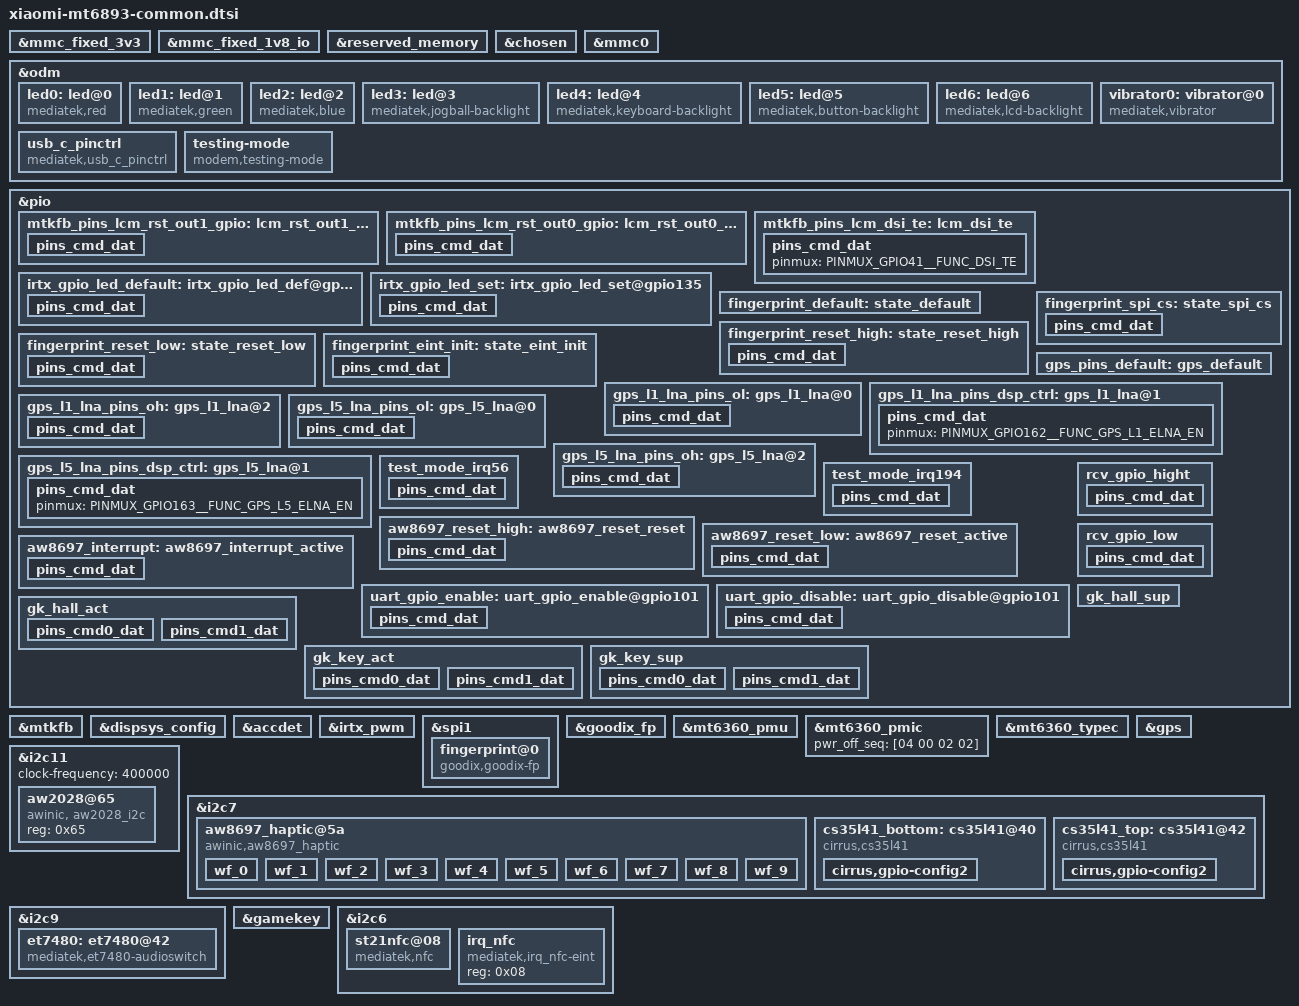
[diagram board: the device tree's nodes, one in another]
/*
 * Mediatek's mt6893 SoC device tree source
 *
 * Copyright (C) 2016 MediaTek Inc.
 * Copyright (C) 2021 XiaoMi, Inc.
 *
 * This program is free software; you can redistribute it and/or modify
 * it under the terms of the GNU General Public License version 2 as
 * published by the Free Software Foundation.
 *
 * This program is distributed in the hope that it will be useful,
 * but WITHOUT ANY WARRANTY; without even the implied warranty of
 * MERCHANTABILITY or FITNESS FOR A PARTICULAR PURPOSE.
 * See http://www.gnu.org/licenses/gpl-2.0.html for more details.
 */
/dts-v1/;
/plugin/;
#include <dt-bindings/interrupt-controller/irq.h>
#include <dt-bindings/interrupt-controller/arm-gic.h>
#include <dt-bindings/spmi/spmi.h>
#include <dt-bindings/pinctrl/mt6885-pinfunc.h>

&mmc_fixed_3v3 {
	status = "okay";
	regulator-name = "mmc_power";
	regulator-min-microvolt = <3300000>;
	regulator-max-microvolt = <3300000>;
	enable-active-high;
	regulator-always-on;
};

&mmc_fixed_1v8_io {
	status = "okay";
	regulator-name = "mmc_io";
	regulator-min-microvolt = <1800000>;
	regulator-max-microvolt = <1800000>;
	enable-active-high;
	regulator-always-on;
};

&reserved_memory {
};

/* chosen */
&chosen {

	atag,videolfb-fb_base_l = <0x7e020000>;
	atag,videolfb-fb_base_h = <0x0>;
	atag,videolfb-islcmfound = <1>;
	atag,videolfb-islcm_inited = <0>;
	atag,videolfb-fps= <6000>;
	atag,videolfb-vramSize= <0x1be0000>;
	atag,videolfb-lcmname=
		"nt35595_fhd_dsi_cmd_truly_nt50358_drv";
};

&mmc0 {
	status = "okay";
	/* pinctrl-names = "default", "state_uhs"; */
	/* pinctrl-0 = <&mmc0_pins_default>; */
	/* pinctrl-1 = <&mmc0_pins_uhs>; */
	bus-width = <8>;
	max-frequency = <5000000>;
	cap-mmc-highspeed;
	no-sdio;
	no-sd;
	vmmc-supply = <&mmc_fixed_3v3>;
	vqmmc-supply = <&mmc_fixed_1v8_io>;
	non-removable;
};

&odm {
	led0:led@0 {
		compatible = "mediatek,red";
		led_mode = <0>;
		data = <1>;
		pwm_config = <0 0 0 0 0>;
	};
	led1:led@1 {
		compatible = "mediatek,green";
		led_mode = <0>;
		data = <1>;
		pwm_config = <0 0 0 0 0>;
	};
	led2:led@2 {
		compatible = "mediatek,blue";
		led_mode = <0>;
		data = <1>;
		pwm_config = <0 0 0 0 0>;
	};
	led3:led@3 {
		compatible = "mediatek,jogball-backlight";
		led_mode = <0>;
		data = <1>;
		pwm_config = <0 0 0 0 0>;
	};
	led4:led@4 {
		compatible = "mediatek,keyboard-backlight";
		led_mode = <0>;
		data = <1>;
		pwm_config = <0 0 0 0 0>;
	};
	led5:led@5 {
		compatible = "mediatek,button-backlight";
		led_mode = <0>;
		data = <1>;
		pwm_config = <0 0 0 0 0>;
	};
	led6:led@6 {
		compatible = "mediatek,lcd-backlight";
		led_mode = <4>;
		data = <1>;
		pwm_config = <0 1 0 0 0>;
	};
	vibrator0:vibrator@0 {
		compatible = "mediatek,vibrator";
		vib_timer = <25>;
		vib_limit = <9>;
		vib_vol= <11>;
	};
	usb_c_pinctrl:usb_c_pinctrl {
		compatible = "mediatek,usb_c_pinctrl";
	};
};

/* DISPSYS GPIO standardization */
&pio {
	mtkfb_pins_lcm_rst_out1_gpio: lcm_rst_out1_gpio {
		pins_cmd_dat {
			pinmux = <PINMUX_GPIO42__FUNC_GPIO42>;
			slew-rate = <1>;
			output-high;
		};
	};

	mtkfb_pins_lcm_rst_out0_gpio: lcm_rst_out0_gpio {
		pins_cmd_dat {
			pinmux = <PINMUX_GPIO42__FUNC_GPIO42>;
			slew-rate = <1>;
			output-low;
		};
	};

	mtkfb_pins_lcm_dsi_te: lcm_dsi_te {
		pins_cmd_dat {
			pinmux = <PINMUX_GPIO41__FUNC_DSI_TE>;
		};
	};
};

&mtkfb {
	pinctrl-names = "lcm_rst_out1_gpio", "lcm_rst_out0_gpio",
		"mode_te_te";
	pinctrl-0 = <&mtkfb_pins_lcm_rst_out1_gpio>;
	pinctrl-1 = <&mtkfb_pins_lcm_rst_out0_gpio>;
	pinctrl-2 = <&mtkfb_pins_lcm_dsi_te>;
	status = "okay";
};

&dispsys_config {
	pinctrl-names =
		"lcm_rst_out1_gpio", "lcm_rst_out0_gpio",
		"mode_te_te";
	pinctrl-0 = <&mtkfb_pins_lcm_rst_out1_gpio>;
	pinctrl-1 = <&mtkfb_pins_lcm_rst_out0_gpio>;
	pinctrl-2 = <&mtkfb_pins_lcm_dsi_te>;
	status = "okay";
};
/* DISPSYS GPIO standardization end */

/* accdet start */
&accdet {
	/* accdet micbias voltage: 0x09:2.85v 0x08:2.8v 0x07,
	 * 2.7v;0x05,2.5v;0x02,1.9v
	 */
	accdet-mic-vol = <8>;
	/* accdet pwm_width, pwm_thresh, fall_delay, rise_delay
	 * debounce0, debounce1, debounce3, debounce4
	 * eint pwm_width, eint pwm_thresh
	 * eint deb(debounce0, debounce1, debounce2, debounce3), inv_debounce
	 */
	headset-mode-setting = <0x500 0x500 1 0x1f0
				0x800 0x800 0x20 0x44
				0x4 0x1
				0x5 0x3 0x3 0x5 0xe>;
	accdet-plugout-debounce = <1>;
	/*1:ACC mode, 2:low cost without in bias, 6:low cost with in bias*/
	accdet-mic-mode = <2>;
	/*0--MD_MAX--UP_MAX--DW_MAX*/
	headset-three-key-threshold = <0 80 220 400>;
	headset-three-key-threshold-CDD = <0 121 192 600>;
	/*0--MD_MAX--VOICE_MAX--UP_MAX--DW_MAX*/
	headset-four-key-threshold = <0 58 121 192 400>;

	/* select VTH to 2v and 500k, use internal resitance */
	eint_use_ext_res = <0>;
	status = "okay";
};
/* accdet end */

/* IRTX GPIO Start */
&irtx_pwm {
	pwm_ch = <0>;
	pinctrl-names = "irtx_gpio_led_default", "irtx_gpio_led_set";
	pinctrl-0 = <&irtx_gpio_led_default>;
	pinctrl-1 = <&irtx_gpio_led_set>;
	status = "okay";
};
&pio {
	/* IRTX GPIO Settings -Start */
	/* default: GPIO0, output, high */
	irtx_gpio_led_default:irtx_gpio_led_def@gpio135 {
		pins_cmd_dat {
			pinmux = <PINMUX_GPIO135__FUNC_GPIO135>;
			slew-rate = <1>;
			bias-disable;
			output-low;
			input-schmitt-enable = <0>;
		};
	};

	irtx_gpio_led_set:irtx_gpio_led_set@gpio135 {
		pins_cmd_dat {
			pinmux = <PINMUX_GPIO135__FUNC_PWM_0>;
			slew-rate = <1>;
			output-high;
		};
	};
}; /* IRTX GPIO Settings -End */

/* FINGERPRINT start */
&spi1 {
	#address-cells = <1>;
	#size-cells = <0>;
	fingerprint@0 {
		compatible = "goodix,goodix-fp";
		reg = <0>;
		spi-max-frequency = <8000000>;
		netlink-event = <30>;
		vfp-supply = <&mt_pmic_vfp_ldo_reg>;
		power-type = <1>;
		status = "okay";
	};
};

&goodix_fp {
	pinctrl-names = "default", "reset_high", "reset_low", "eint_init", "spi_cs";
	pinctrl-0 = <&fingerprint_default>;
	pinctrl-1 = <&fingerprint_reset_high>;
	pinctrl-2 = <&fingerprint_reset_low>;
	pinctrl-3 = <&fingerprint_eint_init>;
	pinctrl-4 = <&fingerprint_spi_cs>;
	fpc,gpio_irq = <&pio 15 0>;
	interrupt-parent = <&pio>;
	interrupts = <15 IRQ_TYPE_EDGE_RISING 15 0>;
	status = "okay";
};

&pio {
	fingerprint_default: state_default {
	};
	fingerprint_reset_high: state_reset_high {
		pins_cmd_dat {
			pinmux = <PINMUX_GPIO14__FUNC_GPIO14>;
			slew-rate = <1>;
			output-high;
		};
	};
	fingerprint_reset_low: state_reset_low {
		pins_cmd_dat {
			pinmux = <PINMUX_GPIO14__FUNC_GPIO14>;
			slew-rate = <1>;
			output-low;
		};
	};
	fingerprint_eint_init: state_eint_init {
		pins_cmd_dat {
			pinmux = <PINMUX_GPIO15__FUNC_GPIO15>;
			slew-rate = <0>;
			bias-pull-up = <MTK_PUPD_SET_R1R0_10>;
			input-schmitt-enable;
		};
	};
	fingerprint_spi_cs: state_spi_cs {
		pins_cmd_dat {
			pinmux = <PINMUX_GPIO157__FUNC_SPI1_A_CSB>;
			slew-rate = <0>;
			bias-disable;
		};
	};
};
/* FINGERPRINT end */

&mt6360_pmu {
	mt6360,intr_gpio_num = <24>; /* direct defined GPIO num */
	mt6360,intr_gpio = <&pio 24 0x0>;
};

&mt6360_pmic {
	pwr_off_seq = [04 00 02 02];
};

&mt6360_typec {
	mt6360pd,intr_gpio_num = <25>; /* direct defined GPIO num */
	mt6360pd,intr_gpio = <&pio 25 0x0>;
};

/* USB SWITCH GPIO start
&pio {
	usb_default: usb_default {
	};

	gpio_redriver_c1_init: c1_init {
		pins_cmd_dat {
			pinmux = <PINMUX_GPIO113__FUNC_GPIO113>;
			slew-rate = <1>;
			output-low;
		};
	};

	gpio_redriver_c1_low: c1_low {
		pins_cmd_dat {
			pinmux = <PINMUX_GPIO113__FUNC_GPIO113>;
			slew-rate = <1>;
			output-low;
		};
	};

	gpio_redriver_c1_hiz: c1_highz {
		pins_cmd_dat {
			pinmux = <PINMUX_GPIO113__FUNC_GPIO113>;
			slew-rate= <0>;
			bias-disable;
		};
	};

	gpio_redriver_c1_high: c1_high {
		pins_cmd_dat {
			pinmux = <PINMUX_GPIO113__FUNC_GPIO113>;
			slew-rate = <1>;
			output-high;
		};
	};

	gpio_redriver_c2_init: c2_init {
		pins_cmd_dat {
			pinmux = <PINMUX_GPIO112__FUNC_GPIO112>;
			slew-rate = <1>;
			output-low;
		};
	};

	gpio_redriver_c2_low: c2_low {
		pins_cmd_dat {
			pinmux = <PINMUX_GPIO112__FUNC_GPIO112>;
			slew-rate = <1>;
			output-low;
		};
	};

	gpio_redriver_c2_hiz: c2_highz {
		pins_cmd_dat {
			pinmux = <PINMUX_GPIO112__FUNC_GPIO112>;
			slew-rate= <0>;
			bias-disable;
		};
	};

	gpio_redriver_c2_high: c2_high {
		pins_cmd_dat {
			pinmux = <PINMUX_GPIO112__FUNC_GPIO112>;
			slew-rate = <1>;
			output-high;
		};
	};

	gpio_u3_switch_sel1: u3_sw_sel1 {
		pins_cmd_dat {
			pinmux = <PINMUX_GPIO111__FUNC_GPIO111>;
			slew-rate = <1>;
			output-low;
		};
	};

	gpio_u3_switch_sel2: u3_sw_sel2 {
		pins_cmd_dat {
			pinmux = <PINMUX_GPIO111__FUNC_GPIO111>;
			slew-rate = <1>;
			output-high;
		};
	};

	gpio_u3_switch_enable: u3_sw_en {
	};

	gpio_u3_switch_disable: u3_sw_dis {
	};
};

&usb_c_pinctrl {
	pinctrl-names = "usb_default",
		"redrv_c1_init",
		"redrv_c1_low",
		"redrv_c1_hiz",
		"redrv_c1_high",
		"redrv_c2_init",
		"redrv_c2_low",
		"redrv_c2_hiz",
		"redrv_c2_high",
		"switch_sel1",
		"switch_sel2",
		"switch_enable",
		"switch_disable";

	pinctrl-0 = <&usb_default>;
	pinctrl-1 = <&gpio_redriver_c1_init>;
	pinctrl-2 = <&gpio_redriver_c1_low>;
	pinctrl-3 = <&gpio_redriver_c1_hiz>;
	pinctrl-4 = <&gpio_redriver_c1_high>;
	pinctrl-5 = <&gpio_redriver_c2_init>;
	pinctrl-6 = <&gpio_redriver_c2_low>;
	pinctrl-7 = <&gpio_redriver_c2_hiz>;
	pinctrl-8 = <&gpio_redriver_c2_high>;
	pinctrl-9 = <&gpio_u3_switch_sel1>;
	pinctrl-10 = <&gpio_u3_switch_sel2>;
	pinctrl-11 = <&gpio_u3_switch_enable>;
	pinctrl-12 = <&gpio_u3_switch_disable>;
	status = "okay";

	usb_switch-data {
		en_pin_num = <0>;
		en_pin_val = <0>;
		sel_pin_num = <111>;
		sel_pin_val = <1>;
		c1_pin_num = <113>;
		c1_pin_val = <2>;
		c2_pin_num = <112>;
		c2_pin_val = <1>;
	};
};
USB SWITCH GPIO end */

/* GPS GPIO standardization start */
&pio {
	gps_pins_default: gps_default {
	};

	gps_l1_lna_pins_ol: gps_l1_lna@0 {
		pins_cmd_dat {
			pinmux = <PINMUX_GPIO162__FUNC_GPIO162>;
			output-low;
		};
	};
	gps_l1_lna_pins_dsp_ctrl: gps_l1_lna@1 {
		pins_cmd_dat {
			pinmux = <PINMUX_GPIO162__FUNC_GPS_L1_ELNA_EN>;
		};
	};
	gps_l1_lna_pins_oh: gps_l1_lna@2 {
		pins_cmd_dat {
			pinmux = <PINMUX_GPIO162__FUNC_GPIO162>;
			output-high;
		};
	};

	gps_l5_lna_pins_ol: gps_l5_lna@0 {
		pins_cmd_dat {
			pinmux = <PINMUX_GPIO163__FUNC_GPIO163>;
			output-low;
		};
	};
	gps_l5_lna_pins_dsp_ctrl: gps_l5_lna@1 {
		pins_cmd_dat {
			pinmux = <PINMUX_GPIO163__FUNC_GPS_L5_ELNA_EN>;
		};
	};
	gps_l5_lna_pins_oh: gps_l5_lna@2 {
		pins_cmd_dat {
			pinmux = <PINMUX_GPIO163__FUNC_GPIO163>;
			output-high;
		};
	};
};

&gps {
	pinctrl-names = "default",
		"gps_l1_lna_disable",
		"gps_l1_lna_dsp_ctrl",
		"gps_l1_lna_enable",
		"gps_l5_lna_disable",
		"gps_l5_lna_dsp_ctrl",
		"gps_l5_lna_enable";
	pinctrl-0 = <&gps_pins_default>;
	pinctrl-1 = <&gps_l1_lna_pins_ol>;
	pinctrl-2 = <&gps_l1_lna_pins_dsp_ctrl>;
	pinctrl-3 = <&gps_l1_lna_pins_oh>;
	pinctrl-4 = <&gps_l5_lna_pins_ol>;
	pinctrl-5 = <&gps_l5_lna_pins_dsp_ctrl>;
	pinctrl-6 = <&gps_l5_lna_pins_oh>;
	status = "okay";
};
/* GPS GPIO standardization end */

&i2c11 {
	clock-frequency = <400000>;
	aw2028@65 {
		compatible = "awinic, aw2028_i2c";
		reg = <0x65>;
		status = "okay";
	};
};

&odm {
	testing-mode {
		compatible = "modem,testing-mode";
		status-gpio = <&pio 56 0>, <&pio 194 0>;
		debounce-time = <30>;
		pinctrl-names = "default";
		pinctrl-0 = <&test_mode_irq56 &test_mode_irq194>;
	};
};

&pio {
	test_mode_irq56: test_mode_irq56 {
                pins_cmd_dat {
			pinmux = <PINMUX_GPIO56__FUNC_GPIO56>;
			drive-strength = <2>;
			bias-disable;
			input-enable;
		};
	};

    test_mode_irq194: test_mode_irq194 {
        	pins_cmd_dat {
			pinmux = <PINMUX_GPIO194__FUNC_GPIO194>;
			drive-strength = <2>;
			bias-disable;
			input-enable;
		};
    };
};

/* AW8697 Haptic start */
&pio {
	aw8697_reset_high: aw8697_reset_reset {
		pins_cmd_dat {
			pinmux = <PINMUX_GPIO129__FUNC_GPIO129>;
			drive-strength = <2>;
			bias-disable;
			output-high;
		};
	};
	aw8697_reset_low: aw8697_reset_active {
		pins_cmd_dat {
			pinmux = <PINMUX_GPIO129__FUNC_GPIO129>;
			drive-strength = <2>;
			bias-disable;
			output-low;
		};
	};
	aw8697_interrupt: aw8697_interrupt_active {
		pins_cmd_dat {
			pinmux = <PINMUX_GPIO22__FUNC_GPIO22>;
			drive-strength = <2>;
			bias-pull-up;
			input-enable;
		};
	};
};

&i2c7 {
	status = "ok";
	aw8697_haptic@5a {
		compatible = "awinic,aw8697_haptic";
		reg = <0x5A>;
		reset-gpio = <&pio 129 0>;
		irq-gpio = <&pio 22 0>;
		vib_mode = < 0 >;   /*mode:   RAM mode->0; CONT mode -> 1*/
		vib_f0_pre = < 1700 >;
		vib_f0_cali_percen = < 7 >;
		vib_cont_drv_lev = < 60 >;
		vib_cont_drv_lvl_ov = < 60 >;
		vib_cont_td = < 0xef >;
		vib_cont_zc_thr = < 0x08f8 >;  /*hq 0x08F8 */
		vib_cont_num_brk = < 3 >;
		vib_f0_coeff = < 260 >; /*Don't modify it    2.604167*/
		vib_f0_trace_parameter = < 9 3 1 31 >;
		vib_bemf_config = < 0 0x08 0x03 0xf8 >;
		vib_sw_brake = < 0x2c >;
		vib_tset = < 0x1a >;
		vib_r_spare = < 0x68 >;
		vib_bstdbg = < 0x30 0xeb 0xd4 0 0 0 >;
		vib_effect_id_boundary = < 10 >;
		vib_effect_max = < 197 >;   /*vib_effect_max must bigger than vib_effect_id*/
		vib_trig_config = < 0 1 0 1 2
						0 1 0 1 2
						0 1 0 1 2 >;
		vib_bst_vol_default = < 0x11 >;
		vib_bst_vol_ram = < 0x11 >;
		vib_bst_vol_rtp = < 0x11 >;
		vib_rtp_time = < 20 20 20 20 20 20 20 20 20000 15000
				 15000 20000 25000 15000 30000 25000 20000 20000 20000 20000
				 20000 20000 20000 20000 20000 20000 20000 20000 20000 20000
				 20000 20000 20000 20000 20000 20000 20000 20000 20000 20000
				 20000 20000 20000 20000 20000 20000 20000 20000 20000 20000
				 20000 20000 20000 20000 20000 20000 20000 20000 20000 20000
				 20000 20000 20000 20000 20000 20000 20000 20000 20000 20000
				 20000 20000 20000 20000 20000 20000 20000 20000 20000 20000
				 20000 20000 20000 20000 20000 20000 20000 20000 20000 20000
				 20000 20000 20000 20000 20000 20000 20000 20000 20000 20000
				 20000 20000 20000 20000 20000 20000 20000 20000 20000 20000
				 20000 20000 20000 20000 20000 20000 20000 20000 20000 20000
				 20000 20000 20000 20000 20000 20000 20000 20000 20000 20000
				 20000 20000 20000 20000 20000 20000 20000 20000 20000 20000
				 20000 20000 20000 20000 20000 20000 20000 20000 20000 20000
				 20000 20000 20000 20000 20000 20000 20000 20000 20000 20000
				 20000 20000 20000 20000 20000 20000 20000 20000 20000 20000
				 20000 20000 20000 20000 20000 >;
		pinctrl-names = "aw8697_reset_reset","aw8697_reset_active","aw8697_interrupt_active";
		pinctrl-0 = <&aw8697_reset_low>;
		pinctrl-1 = <&aw8697_reset_high>;
		pinctrl-2 = <&aw8697_interrupt>;
		status = "ok";
		wf_0 {
			/*CLICK*/
			mtk,effect-id = <0>;
			mtk,wf-vmax-mv = <3600>;
			mtk,wf-pattern = [3e 3e];
			mtk,wf-brake-pattern = [02 01 00 00];
			mtk,wf-play-rate-us = <20000>;
		};
		wf_1 {
			/*DOUBLE CLICK*/
			mtk,effect-id = <1>;
			mtk,wf-vmax-mv = <3600>;
			mtk,wf-pattern = [7e 3e];
			mtk,wf-brake-pattern = [03 01 00 00];
			mtk,wf-play-rate-us = <20000>;
		};
		wf_2 {
			/*TICK*/
			mtk,effect-id = <2>;
			mtk,wf-vmax-mv = <3600>;
			mtk,wf-pattern = [7e 3e];
			mtk,wf-brake-pattern = [02 01 00 00];
			mtk,wf-play-rate-us = <20000>;
		};
		wf_3 {
			/*THUD*/
			mtk,effect-id = <3>;
			mtk,wf-vmax-mv = <3600>;
			mtk,wf-pattern = [3e 3e];
			mtk,wf-brake-pattern = [02 01 00 00];
			mtk,wf-play-rate-us = <20000>;
		};
		wf_4 {
			/*POP*/
			mtk,effect-id = <4>;
			mtk,wf-vmax-mv = <3600>;
			mtk,wf-pattern = [3e 3e];
			mtk,wf-brake-pattern = [02 01 00 00];
			mtk,wf-play-rate-us = <28000>;
		};
		wf_5 {
			/*HEAVY CLICK*/
			mtk,effect-id = <5>;
			mtk,wf-vmax-mv = <3600>;
			mtk,wf-pattern = [7e 7e 7e];
			mtk,wf-brake-pattern = [03 03 01 00];
			mtk,wf-play-rate-us = <20000>;
		};
		wf_6 {
			/*id 6*/
			mtk,effect-id = <6>;
			mtk,wf-vmax-mv = <3600>;
			mtk,wf-pattern = [3e 3e];
			mtk,wf-brake-pattern = [02 01 00 00];
			mtk,wf-play-rate-us = <20000>;
		};
		wf_7 {
			/*id 7*/
			mtk,effect-id = <7>;
			mtk,wf-vmax-mv = <3600>;
			mtk,wf-pattern = [3e 3e];
			mtk,wf-brake-pattern = [02 01 00 00];
			mtk,wf-play-rate-us = <20000>;
		};
		wf_8 {
			/*id 8*/
			mtk,effect-id = <8>;
			mtk,wf-vmax-mv = <3600>;
			mtk,wf-pattern = [3e 3e];
			mtk,wf-brake-pattern = [02 01 00 00];
			mtk,wf-play-rate-us = <20000>;
		};
		wf_9 {
			/*id 9*/
			mtk,effect-id = <9>;
			mtk,wf-vmax-mv = <3600>;
			mtk,wf-pattern = [3e 3e];
			mtk,wf-brake-pattern = [02 01 00 00];
			mtk,wf-play-rate-us = <20000>;
		};
	};
};
/* AW8697 Haptic end */

&pio {
	uart_gpio_enable: uart_gpio_enable@gpio101 {
		pins_cmd_dat {
			pinmux = <PINMUX_GPIO101__FUNC_GPIO101>;
			slew-rate = <1>;
			bias-disable;
			output-low;
		};
	};

	uart_gpio_disable: uart_gpio_disable@gpio101 {
		pins_cmd_dat {
			pinmux = <PINMUX_GPIO101__FUNC_GPIO101>;
			slew-rate = <1>;
			bias-disable;
			output-high;
		};
	};
};


&i2c9 {
	et7480: et7480@42 {
		status = "ok";
		compatible = "mediatek,et7480-audioswitch";
		reg = <0x42>;
		pinctrl-names = "uart_enable", "uart_disable";
		pinctrl-0 = <&uart_gpio_enable>;
		pinctrl-1 = <&uart_gpio_disable>;
	};
};

&accdet {
	/* accdet micbias voltage: 0x09:2.85v 0x08:2.8v 0x07,
	 * 2.7v;0x05,2.5v;0x02,1.9v
	 */
	accdet-mic-vol = <5>;

	/*1:ACC mode, 2:low cost without in bias, 6:low cost with in bias*/
	accdet-mic-mode = <2>;

	et7480-i2c-handle = <&et7480>;
};

&pio {
	rcv_gpio_hight: rcv_gpio_hight {
		pins_cmd_dat {
			pinmux = <PINMUX_GPIO54__FUNC_GPIO54>;
			drive-strength = <2>;
			bias-disable;
			output-high;
		};
	};
	rcv_gpio_low: rcv_gpio_low {
		pins_cmd_dat {
			pinmux = <PINMUX_GPIO54__FUNC_GPIO54>;
			drive-strength = <2>;
			bias-disable;
			output-low;
		};
	};
};

/* Audio Start */
&i2c7 {
	status = "okay";
	cs35l41_bottom: cs35l41@40 {
		compatible = "cirrus,cs35l41";
		#sound-dai-cells = <0>;
		reg = <0x40>;
		reset-gpio = <&pio 30 0>;
		interrupt-parent = <&pio>;
		interrupts = <31 IRQ_TYPE_LEVEL_LOW 31 0>;
		irq-gpio = <&pio 31 0>;
		cirrus,boost-peak-milliamp = <4500>;
		cirrus,boost-ind-nanohenry = <1000>;
		cirrus,boost-cap-microfarad = <15>;
		cirrus,asp-sdout-hiz = <1>;
		cirrus,gpio-config2 {
			cirrus,gpio-src-select = <0x4>;
			cirrus,gpio-output-enable;
		};
	};

	cs35l41_top: cs35l41@42 {
		compatible = "cirrus,cs35l41";
		#sound-dai-cells = <0>;
		reg = <0x42>;
		reset-gpio = <&pio 30 0>;
		interrupt-parent = <&pio>;
		interrupts = <113 IRQ_TYPE_LEVEL_LOW 113 0>;
		irq-gpio = <&pio 113 0>;
		cirrus,boost-peak-milliamp = <4500>;
		cirrus,boost-ind-nanohenry = <1000>;
		cirrus,boost-cap-microfarad = <15>;
		cirrus,asp-sdout-hiz = <1>;
		cirrus,tuning-has-prefix;
		pinctrl-names = "rcv_gpio_hight", "rcv_gpio_low";
		pinctrl-0 = <&rcv_gpio_hight>;
		pinctrl-1 = <&rcv_gpio_low>;
		cirrus,gpio-config2 {
			cirrus,gpio-src-select = <0x4>;
			cirrus,gpio-output-enable;
		};
	};
};
/* Audio End */

/*GAMEKEY start*/
&gamekey {
    status = "ok";
    key_left = <&pio 111 0x00>;
    hall_left = <&pio 4 0x00>;
    key_right = <&pio 112 0x00>;
    hall_right = <&pio 5 0x00>;
    debounce_time = <5>;        /*unit in ms*/
    pinctrl-names = "gamekey_active", "gamekey_suspend";
    pinctrl-0 = <&gk_hall_act &gk_key_act>;
    pinctrl-1 = <&gk_hall_sup &gk_key_sup>;
};

&pio {
	gk_hall_act: gk_hall_act {
		pins_cmd0_dat {
			pinmux = <PINMUX_GPIO4__FUNC_GPIO4>;
			input-enable;
			bias-disable;
		};

		pins_cmd1_dat {
			pinmux = <PINMUX_GPIO5__FUNC_GPIO5>;
			input-enable;
			bias-disable;
		};
	};

	gk_hall_sup: gk_hall_sup {
	};

	gk_key_act: gk_key_act {
		pins_cmd0_dat {
			pinmux = <PINMUX_GPIO111__FUNC_GPIO111>;
			input-enable;
			bias-pull-up;
			drive-strength = <2>;
		};

		pins_cmd1_dat {
			pinmux = <PINMUX_GPIO112__FUNC_GPIO112>;
			input-enable;
			bias-pull-up;
			drive-strength = <2>;
		};
	};

	gk_key_sup: gk_key_sup {
		pins_cmd0_dat {
			pinmux = <PINMUX_GPIO111__FUNC_GPIO111>;
			bias-disable;
		};

		pins_cmd1_dat {
			pinmux = <PINMUX_GPIO112__FUNC_GPIO112>;
			bias-disable;
		};
	};
};
/*GAMEKEY end*/

//ST NFC for Mediateckstart
&i2c6 {
    st21nfc@08 {
      compatible = "mediatek,nfc";
      reg = <0x08>;
      gpio-irq = <11>;
      gpio-irq-std = <&pio 11 0x00>;
      interrupt-parent = <&pio>;
      interrupts = <11 IRQ_TYPE_LEVEL_HIGH 11 0>;
      gpio-rst = <10>;
      gpio-rst-std = <&pio 10 0x0>;
 //     st,clkreq_gpio = <&pio 25 0x0>;
      interrupt-names = "nfc_irq";
      pinctrl-names = "default", "nfc_active", "nfc_suspend";
      pinctrl-0 = <&nfc_default>;
      pinctrl-1 = <&nfc_int_active &nfc_enable_active>;
 //       &nfc_clk_req_active>;
      pinctrl-2 = <&nfc_int_suspend &nfc_enable_suspend>;
//         &nfc_clk_req_suspend>;
    };
        irq_nfc: irq_nfc {
                compatible = "mediatek,irq_nfc-eint";
                reg = <0x08>;
        };
};
//NFC end 

#include "mediatek/cust_mt6893_touch_1080x2300.dtsi"
#include "mediatek/cust_mt6893_camera.dtsi"
#include <k6893v1_64/cust.dtsi>
/*End of this file, DO NOT ADD ANYTHING HERE*/
